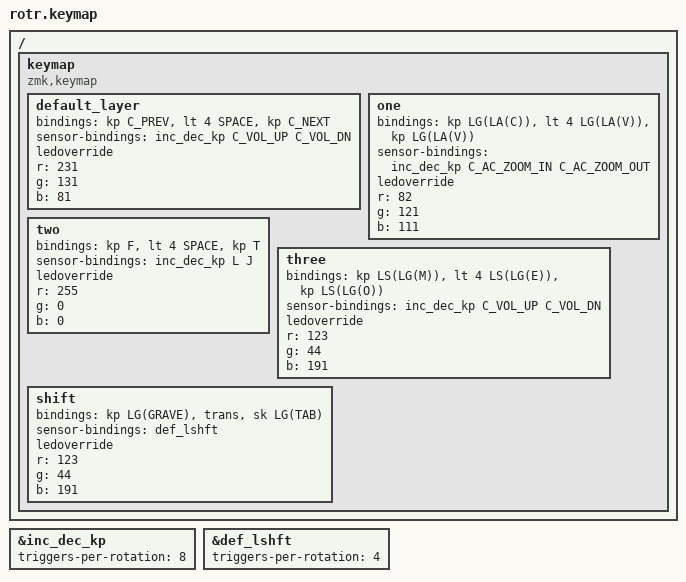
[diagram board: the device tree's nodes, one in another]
#include <behaviors.dtsi>
#include <dt-bindings/zmk/keys.h>
#include <dt-bindings/zmk/rgb.h>
#include <dt-bindings/zmk/bt.h>

&inc_dec_kp {
	triggers-per-rotation = <8>;
};

&def_lshft {
	triggers-per-rotation = <4>;
};

/ {
	keymap {
		compatible = "zmk,keymap";

		default_layer {
			//MUSIC LAYER | PREV | PLAY/PAUSE | NEXT
			bindings = <&kp C_PREV &lt 4 SPACE &kp C_NEXT>;
			sensor-bindings = <&inc_dec_kp C_VOL_UP C_VOL_DN>;
			ledoverride;
            			r = <231>;
		    		g = <131>;
            			b = <81>;

			};
		one {
			//FIGMA LAYER | PREV | PLAY/PAUSE | NEXT
			bindings = <&kp LG(LA(C)) &lt 4 LG(LA(V)) &kp LG(LA(V))>;
			sensor-bindings = <&inc_dec_kp C_AC_ZOOM_IN C_AC_ZOOM_OUT>;
			ledoverride;
          		  	r = <82>;
            			g = <121>;
            			b = <111>;

			
			};
		two {
			//YOUTUBE LAYER | FullScreen | PLAY/PAUSE | Cinema Mode
			bindings = <&kp F &lt 4 SPACE &kp T>;
			sensor-bindings = <&inc_dec_kp L J>;
			ledoverride;
            			r = <255>;
            			g = <0>;
            			b = <0>;

			};
		three {
			//TEAMS LAYER | PREV | PLAY/PAUSE | NEXT
			bindings = <&kp LS(LG(M)) &lt 4 LS(LG(E))  &kp LS(LG(O))>;
			sensor-bindings = <&inc_dec_kp C_VOL_UP C_VOL_DN>;
			ledoverride;
            			r = <123>;
            			g = <44>;
            			b = <191>;
			};
		shift {
			//Stuff i can use on ALL layers |  | Stuff i can use on ALL layers | [Layer Switch]
			bindings = <&kp LG(GRAVE) &trans &sk LG(TAB)>;
			sensor-bindings = <&def_lshft>;
			ledoverride;
            			r = <123>;
            			g = <44>;
            			b = <191>;
			};
	};
};
